# RL6678_IP_SVD register map
Vendor: Realtek
Registers are 32-bit, read-write, reset 0x0 unless marked. A register's access mark holds for its fields unless they carry their own. Offsets are from the block's base; [hi:lo] are bit positions; <NAME> marks a mode.

## SWR1_REG
Base 0x42008880
Same registers: SWR2_REG 0x420088C0
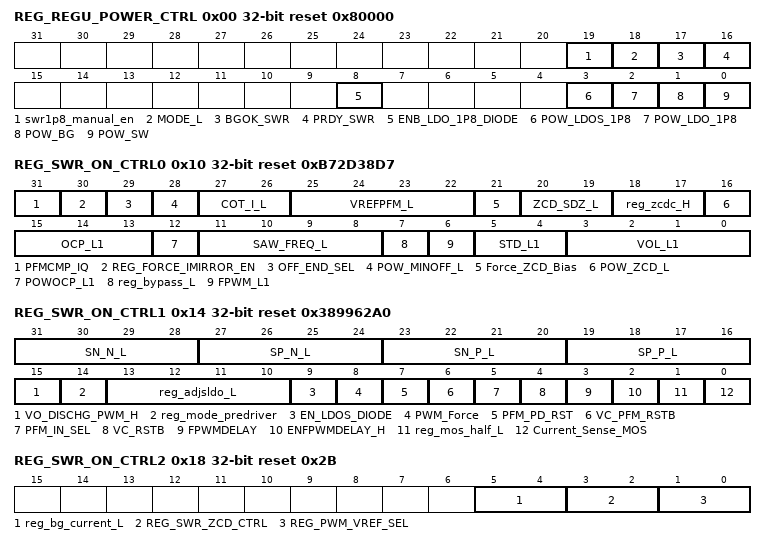
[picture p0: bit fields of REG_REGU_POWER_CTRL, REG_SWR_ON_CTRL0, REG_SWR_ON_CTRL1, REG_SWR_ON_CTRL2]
0x00 REG_REGU_POWER_CTRL access per field reset 0x80000
  [19] swr1p8_manual_en rw — SWR manual mode enable. In manual mode,SWR's pwm_force pwm_mode use register
  [18] MODE_L ro — SWR current mode for debug
  [17] BGOK_SWR ro — SWR bang ok flag by analog
  [16] PRDY_SWR ro — SWR power ready flag by analog
  [8] ENB_LDO_1P8_DIODE rw — control bit LDO diode for inrush current
  [3] POW_LDOS_1P8 rw — 1:power small LDO
  [2] POW_LDO_1P8 rw — 1:power LDO mode
  [1] POW_BG rw — 1:power swr bg for swr mem . Note:other SWR's bg are shared with POR regu
  [0] POW_SW rw — 1:power swr
0x10 REG_SWR_ON_CTRL0 reset 0xB72D38D7
  [31] PFMCMP_IQ — PFM comparator bias, 0: 50nA 1:250nA
  [30] REG_FORCE_IMIRROR_EN — Only valid for MEM, null0 for PSRAM // Force SWR IBIAS Generation circuit enable 1: force enable (need enable this circuit before enable small LDO for SWR, or any LDO using SWR IBIAS) 0: non force, IBIAS enable listen to REG_*_POW_SW (default)
  [29] OFF_END_SEL — COT off time controlled by, 0: ZCD 1: min off time
  [28] POW_MINOFF_L — 0:normal current 1:increase OCP cmp current
  [27:26] COT_I_L — COT ON Current 00:150nA 01:150nA+100nA 10:150nA+150nA 11:150nA+250nA
  [25:22] VREFPFM_L — SWR/LDO 0000 1.200 0001 1.250 0010 1.300 0011 1.350 0100 1.400 0101 1.450 0110 1.500 0111 1.550 1000 1.600 1001 1.650 1010 1.700 1011 1.750 1100 1.800 1101 1.850 1110 1.900 1111 1.950
  [21] Force_ZCD_Bias — 0:ZCD bias on after SS 1:ZCD bias on when ZCD enable
  [20:19] ZCD_SDZ_L — Increase ZCD delay cell
  [18:17] reg_zcdc_H — 00:0.1u 01:0.2u(PFM) 10:0.7u(PWM) 11:0.8u
  [16] POW_ZCD_L — Enable ZCD
  [15:13] OCP_L1 — FOR MEM FOR PSRAM PWM current(A) PFM current (A) PWM current(A) PFM current(A) 000 0.601 0.201 000 0.398 0.178 001 0.732 0.268 001 0.486 0.222 010 0.864 0.335 010 0.573 0.266 011 0.995 0.402 011 0.660 0.310 100 1.126 0.468 100 0.747 0.354 101 1.257 0.535 101 0.834 0.398 110 1.387 0.601 110 0.920 0.442 111 1.518 VIN/10 111 1.008 VIN/10
  [12] POWOCP_L1 — POWOCP_L1=1=> enable over current protection
  [11:8] SAW_FREQ_L — 0000 458.0k 0001 680.2k 0010 898.9k 0011 1.113M 0100 1.321M 0101 1.522M 0110 1.716M 0111 1.902M 1000 2.087M 1001 2.258M 1010 2.426M 1011 2.582M 1100 2.743M 1101 2.888M 1110 3.035M 1111 3.165M
  [7] reg_bypass_L — 1:bypass SSR latch
  [6] FPWM_L1 — FPWM_L1 = 1 => force PWM FPWM_L1 = 0 => force PFM
  [5:4] STD_L1 — STD_L1<1:0> time 00 750u 01 1.5m 10 3m 11 6m
  [3:0] VOL_L1 — VREF 0.6V 0.575V 0000 1.426 1.367 0001 1.455 1.394 0010 1.501 1.438 0011 1.549 1.484 0100 1.583 1.517 0101 1.637 1.569 0110 1.695 1.624 0111 1.736 1.664 1000 1.801 1.726 1001 1.871 1.793 1010 1.921 1.841 1011 2.001 1.918 1100 2.088 2.001 1101 2.150 2.060 1110 2.251 2.157 1111 2.362 2.264
0x14 REG_SWR_ON_CTRL1 reset 0x389962A0
  [31:28] SN_N_L — NGATE NMOS driving
  [27:24] SP_N_L — NGATE PMOS driving
  [23:20] SN_P_L — PGATE NMOS driving
  [19:16] SP_P_L — PGATE PMOS driving
  [15] VO_DISCHG_PWM_H — 1:dummy loading 5mA
  [14] reg_mode_predriver — 1:3 level predriver
  [13:10] reg_adjsldo_L — 0000 1.413 0001 1.451 0010 1.491 0011 1.534 0100 1.579 0101 1.627 0110 1.678 0111 1.732 1000 1.790 1001 1.852 1010 1.918 1011 1.989 1100 2.065 1101 2.148 1110 2.238 1111 2.335
  [9] EN_LDOS_DIODE — 1 : LDOS diode enable
  [8] PWM_Force — 0: PWM bias enabled only at PWM mode 1: Force PWM bias enable when in PWM/PFM mode
  [7] PFM_PD_RST — 1: When leave PFM mode, COT logic is reset
  [6] VC_PFM_RSTB — When into PFM, VC is, 0: clamped (bit 40 also =1) 1. floating
  [5] PFM_IN_SEL — Power MOS into PFM when PFM CTRL, 0: rising 1: falling
  [4] VC_RSTB — Before SS VC is, 0: pulled low 1: floating
  [3] FPWMDELAY — 1:PFM<=>PWM PFM/PWM change by using DFF(CKMOD)
  [2] ENFPWMDELAY_H — 1:PFM=>PWM delay PWM enable and wait one clock cycle then PFM off
  [1] reg_mos_half_L — 1:power mos half
  [0] Current_Sense_MOS — 1: current sensing MOS for large OC current
0x18 REG_SWR_ON_CTRL2 reset 0x2B
  [5:4] reg_bg_current_L — Only valid for MEM, null1 for PSRAM 00:23.9n 01:54.6n 10:117.8n
  [3:2] REG_SWR_ZCD_CTRL — // SWR ZCD CTRL control <1>1:double current <0>1'b1: force in CCM/DCM boundary mode(default), 1'b0 : no boundary
  [1:0] REG_PWM_VREF_SEL — PWM_VREF_SEL 2'b11 0P600V for SWR1P8V (DDR2) (default) 2'b10 0P575V for SWR1P725V (DDR2 trim) 2'b01 0P500V for SWR1P5V (DDR3) 2'b00 0P450V for SWR1P35V (DDR3L)
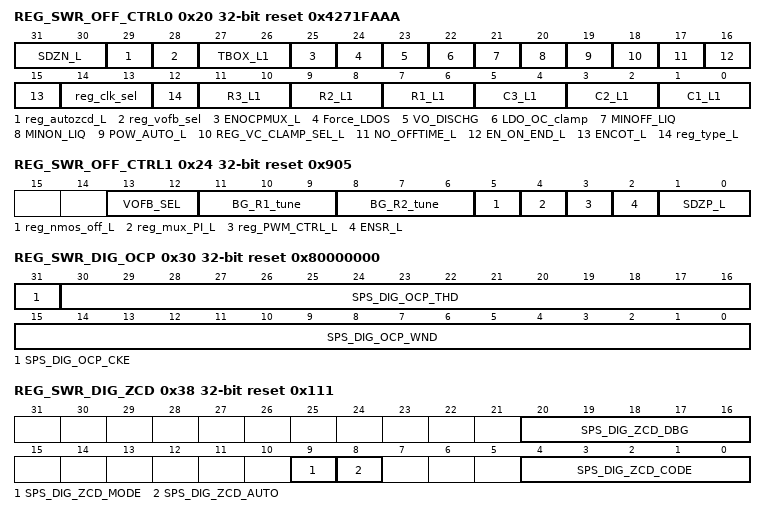
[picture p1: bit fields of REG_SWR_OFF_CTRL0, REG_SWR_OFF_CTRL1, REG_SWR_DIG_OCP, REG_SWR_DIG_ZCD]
0x20 REG_SWR_OFF_CTRL0 reset 0x4271FAAA
  [31:30] SDZN_L — Nonoverlap delay cell for NMOS
  [29] reg_autozcd_L — 0:register 1:10000
  [28] reg_vofb_sel — 0:vo15 1:LX_SPS
  [27:26] TBOX_L1 — TBOX_L1<1:0> output 00 CKOVER/RAMPOVER 01 NI/PI 10 CKSS/SSOVER 11 i/NIOFF_H
  [25] ENOCPMUX_L — 1:OCP signal control by MUX 0:OCP signal control by I
  [24] Force_LDOS — 1:LDOS force on
  [23] VO_DISCHG — 1:VO with 1mA discharge
  [22] LDO_OC_clamp — 0:OC clamp with P/NMOS 1:OC clamp with PMOS
  [21] MINOFF_LIQ — 0:Min. off circuit always on 1:Min. off circuit pulse on
  [20] MINON_LIQ — 0:Min. on circuit always on 1:Min. on circuit pulse on
  [19] POW_AUTO_L — 1:auto PFM/PWM 0:register control
  [18] REG_VC_CLAMP_SEL_L — 0:unity gain feedback clamp VC=VREF 1.orignal clamp(roll back option)
  [17] NO_OFFTIME_L — 0:from min OFF time(PFM COT) 1:always on
  [16] EN_ON_END_L — 1:EN min OFF time (PFM COT)
  [15] ENCOT_L — 1:PFM COT
  [14:13] reg_clk_sel — 00:out of phase CKSS 01:out of phase PWM_CTRIL 10:ckout 11:HG
  [12] reg_type_L — 1:type3 0:type2
  [11:10] R3_L1 — 00 => 36k 01 => 30k 10 => 24k 11 => 24k
  [9:8] R2_L1 — 00 => 0.4M 01 => 0.3M 10 => 0.2M 11 => 0.1M
  [7:6] R1_L1 — 00 => 900k 01 => 720k 10 => 900k 11 => 1080k
  [5:4] C3_L1 — 00 => 1.59p 01 => 3.2p 10 => 4.76p 11 => 6.34p
  [3:2] C2_L1 — 00 => 13f 01 => 26f 10 => 39f 11 => 41f
  [1:0] C1_L1 — 00 => 1.03p 01 => 2.06p 10 => 3.1p 11 => 4.12p
0x24 REG_SWR_OFF_CTRL1 reset 0x905
  [13:12] VOFB_SEL — // output feedback select, need set bits before SWR enable // 00 (default) from SWR internal PAD // 01 : from SWR external PAD_1 // 10: from SWR external PAD_2 // 11: from SWR external PAD_3
  [11:9] BG_R1_tune — BG R2電阻調整
  [8:6] BG_R2_tune — BG R1電阻調整
  [5] reg_nmos_off_L — 0:normal 1:NMOS always off
  [4] reg_mux_PI_L — 1:PI (original) 0:i
  [3] reg_PWM_CTRL_L — 0:internal PWM 1:external PWM
  [2] ENSR_L — 1:with SSR latch
  [1:0] SDZP_L — Nonoverlap delay cell for PMOS
0x30 REG_SWR_DIG_OCP reset 0x80000000
  [31] SPS_DIG_OCP_CKE — SPS OCP clock enable
  [30:16] SPS_DIG_OCP_THD — SPS OCP event threshold
  [15:0] SPS_DIG_OCP_WND — SPS OCP time window
0x38 REG_SWR_DIG_ZCD access per field reset 0x111
  [20:16] SPS_DIG_ZCD_DBG ro — The acture zcd code used for SPS core
  [9] SPS_DIG_ZCD_MODE rw — SPS ZCD SW mode enable
  [8] SPS_DIG_ZCD_AUTO rw — SPS HW ZCD code auto count function enable
  [4:0] SPS_DIG_ZCD_CODE rw — SPS_DIG_ZCD_CODE,this is used for SW mode
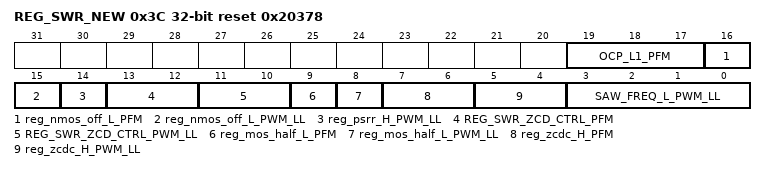
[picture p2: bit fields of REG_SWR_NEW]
0x3C REG_SWR_NEW reset 0x20378
  [19:17] OCP_L1_PFM — FOR MEM FOR PSRAM PWM current(A) PFM current (A) PWM current(A) PFM current(A) 000 0.601 0.201 000 0.398 0.178 001 0.732 0.268 001 0.486 0.222 010 0.864 0.335 010 0.573 0.266 011 0.995 0.402 011 0.660 0.310 100 1.126 0.468 100 0.747 0.354 101 1.257 0.535 101 0.834 0.398 110 1.387 0.601 110 0.920 0.442 111 1.518 VIN/10 111 1.008 VIN/10
  [16] reg_nmos_off_L_PFM — 0:normal 1:NMOS always off PFM mode parametr
  [15] reg_nmos_off_L_PWM_LL — 0:normal 1:NMOS always off PWM mode parametr for system low load
  [14] reg_psrr_H_PWM_LL — 0:default 1:res+cap PWM mode parametr for system low load
  [13:12] REG_SWR_ZCD_CTRL_PFM — // SWR ZCD CTRL control <1>1:double current <0>1'b1: force in CCM/DCM boundary mode(default), 1'b0 : no boundary PFM mode parametr
  [11:10] REG_SWR_ZCD_CTRL_PWM_LL — // SWR ZCD CTRL control <1>1:double current <0>1'b1: force in CCM/DCM boundary mode(default), 1'b0 : no boundary PWM mode parametr for system low load
  [9] reg_mos_half_L_PFM — 1:power mos half PFM mode parametr
  [8] reg_mos_half_L_PWM_LL — 1:power mos half PWM mode parametr for system low load
  [7:6] reg_zcdc_H_PFM — 00:0.1u 01:0.2u(PFM) 10:0.7u(PWM) 11:0.8u PFM mode parametr
  [5:4] reg_zcdc_H_PWM_LL — 00:0.1u 01:0.2u(PFM) 10:0.7u(PWM) 11:0.8u PWM mode parametr for system low load
  [3:0] SAW_FREQ_L_PWM_LL — 0000 458.0k 0001 680.2k 0010 898.9k 0011 1.113M 0100 1.321M 0101 1.522M 0110 1.716M 0111 1.902M 1000 2.087M 1001 2.258M 1010 2.426M 1011 2.582M 1100 2.743M 1101 2.888M 1110 3.035M 1111 3.165M PWM mode parametr for system low load
